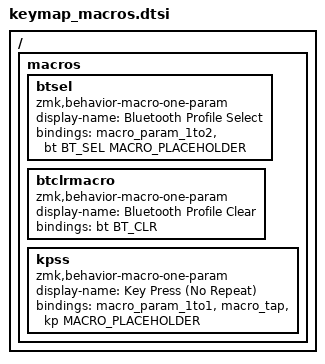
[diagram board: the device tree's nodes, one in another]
/ {

    macros {
        // Select bluetooth profile helper for behaviors
        btsel: btsel {
            display-name = "Bluetooth Profile Select";
            compatible = "zmk,behavior-macro-one-param";
            #binding-cells = <1>;
            bindings = <&macro_param_1to2>
                , <&bt BT_SEL MACRO_PLACEHOLDER>;
        };

        // Select bluetooth profile helper for behaviors
        btclrmacro: btclrmacro {
            display-name = "Bluetooth Profile Clear";
            compatible = "zmk,behavior-macro-one-param";
            #binding-cells = <1>;
            bindings = <&bt BT_CLR>;
        };

        // Macro KP
        kpss: kpss {
            display-name = "Key Press (No Repeat)";
            compatible = "zmk,behavior-macro-one-param";
            #binding-cells = <1>;
            bindings = <&macro_param_1to1>
                , <&macro_tap &kp MACRO_PLACEHOLDER>;
        };
    };
};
